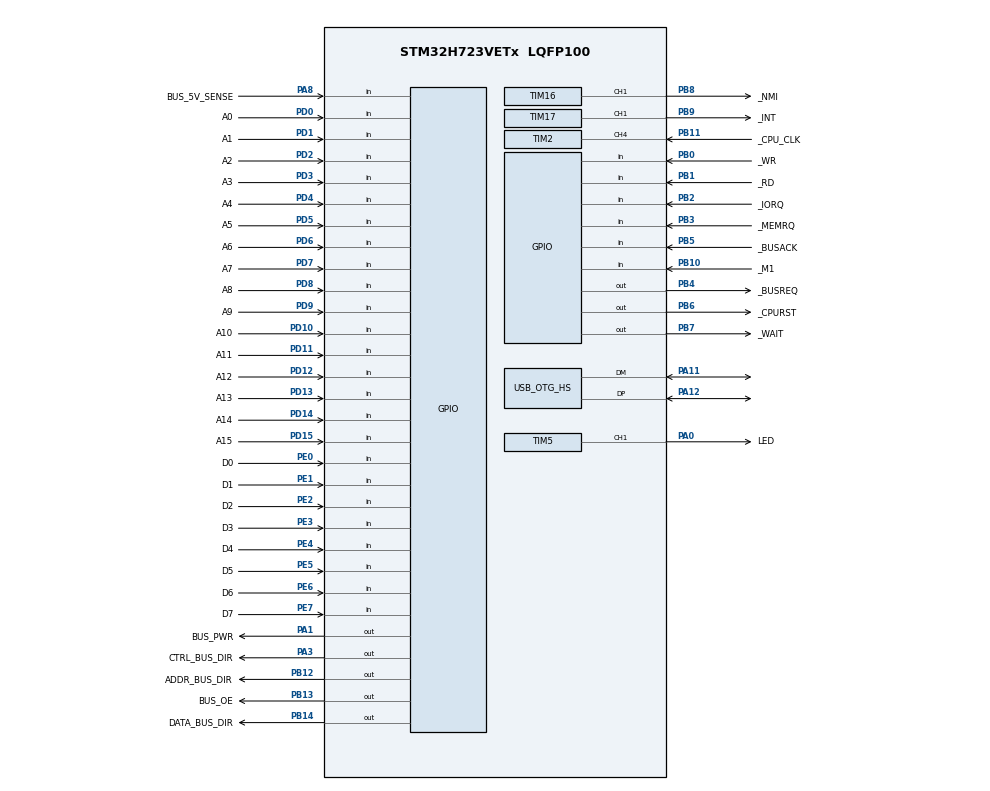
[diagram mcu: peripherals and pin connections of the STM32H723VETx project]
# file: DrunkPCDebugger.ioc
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CORTEX_M7.default_mode_Activation=1
Mcu.Family=STM32H7
Mcu.Name=STM32H723VETx
Mcu.Package=LQFP100
NVIC.OTG_HS_IRQn=true\:0\:0\:false\:false\:true\:false\:true\:true
NVIC.PriorityGroup=NVIC_PRIORITYGROUP_4
PA0.GPIO_Label=LED
PA0.GPIO_PuPd=GPIO_PULLUP
PA0.Signal=S_TIM5_CH1
PA1.GPIO_Label=BUS_PWR
PA1.Signal=GPIO_Output
PA11.Mode=Device_Only_FS
PA11.Signal=USB_OTG_HS_DM
PA12.Mode=Device_Only_FS
PA12.Signal=USB_OTG_HS_DP
PA13(JTMS/SWDIO).Mode=Serial_Wire
PA13(JTMS/SWDIO).Signal=DEBUG_JTMS-SWDIO
PA14(JTCK/SWCLK).Mode=Serial_Wire
PA14(JTCK/SWCLK).Signal=DEBUG_JTCK-SWCLK
PA3.GPIO_Label=CTRL_BUS_DIR
PA3.Signal=GPIO_Output
PA8.GPIO_Label=BUS_5V_SENSE
PA8.Signal=GPIO_Input
PB0.GPIO_Label=_WR
PB0.Signal=GPIO_Input
PB1.GPIO_Label=_RD
PB1.Signal=GPIO_Input
PB10.GPIO_Label=_M1
PB10.Signal=GPIO_Input
PB11.GPIO_Label=_CPU_CLK
PB11.Signal=S_TIM2_CH4
PB12.GPIO_Label=ADDR_BUS_DIR
PB12.Signal=GPIO_Output
PB13.GPIO_Label=BUS_OE
PB13.Signal=GPIO_Output
PB14.GPIO_Label=DATA_BUS_DIR
PB14.Signal=GPIO_Output
PB2.GPIO_Label=_IORQ
PB2.Signal=GPIO_Input
PB3(JTDO/TRACESWO).GPIO_Label=_MEMRQ
PB3(JTDO/TRACESWO).Signal=GPIO_Input
PB4(NJTRST).GPIO_Label=_BUSREQ
PB4(NJTRST).PinState=GPIO_PIN_SET
PB4(NJTRST).Signal=GPIO_Output
PB5.GPIO_Label=_BUSACK
PB5.Signal=GPIO_Input
PB6.GPIO_Label=_CPURST
PB6.PinState=GPIO_PIN_SET
PB6.Signal=GPIO_Output
PB7.GPIO_Label=_WAIT
PB7.GPIO_PuPd=GPIO_PULLUP
PB7.Signal=GPIO_Output
PB8.GPIO_Label=_NMI
PB8.GPIO_PuPd=GPIO_PULLUP
PB8.Signal=S_TIM16_CH1
PB9.GPIO_Label=_INT
PB9.GPIO_PuPd=GPIO_PULLUP
PB9.Signal=S_TIM17_CH1
PD0.GPIO_Label=A0
PD0.Signal=GPIO_Input
PD1.GPIO_Label=A1
PD1.Signal=GPIO_Input
PD10.GPIO_Label=A10
PD10.Signal=GPIO_Input
PD11.GPIO_Label=A11
PD11.Signal=GPIO_Input
PD12.GPIO_Label=A12
PD12.Signal=GPIO_Input
PD13.GPIO_Label=A13
PD13.Signal=GPIO_Input
PD14.GPIO_Label=A14
PD14.Signal=GPIO_Input
PD15.GPIO_Label=A15
PD15.Signal=GPIO_Input
PD2.GPIO_Label=A2
PD2.Signal=GPIO_Input
PD3.GPIO_Label=A3
PD3.Signal=GPIO_Input
PD4.GPIO_Label=A4
PD4.Signal=GPIO_Input
PD5.GPIO_Label=A5
PD5.Signal=GPIO_Input
PD6.GPIO_Label=A6
PD6.Signal=GPIO_Input
PD7.GPIO_Label=A7
PD7.Signal=GPIO_Input
PD8.GPIO_Label=A8
PD8.Signal=GPIO_Input
PD9.GPIO_Label=A9
PD9.Signal=GPIO_Input
PE0.GPIO_Label=D0
PE0.Signal=GPIO_Input
PE1.GPIO_Label=D1
PE1.Signal=GPIO_Input
PE2.GPIO_Label=D2
PE2.Signal=GPIO_Input
PE3.GPIO_Label=D3
PE3.Signal=GPIO_Input
PE4.GPIO_Label=D4
PE4.Signal=GPIO_Input
PE5.GPIO_Label=D5
PE5.Signal=GPIO_Input
PE6.GPIO_Label=D6
PE6.Signal=GPIO_Input
PE7.GPIO_Label=D7
PE7.Signal=GPIO_Input
PH0-OSC_IN.Mode=HSE-External-Oscillator
PH0-OSC_IN.Signal=RCC_OSC_IN
PH1-OSC_OUT.Mode=HSE-External-Oscillator
PH1-OSC_OUT.Signal=RCC_OSC_OUT
ProjectManager.HeapSize=0x200
ProjectManager.StackSize=0x400
ProjectManager.TargetToolchain=Makefile
RCC.ADCFreq_Value=50390625
RCC.APB1Freq_Value=137500000
RCC.APB2Freq_Value=137500000
RCC.APB3Freq_Value=137500000
RCC.APB4Freq_Value=137500000
RCC.CortexFreq_Value=550000000
RCC.D1PPRE=RCC_APB3_DIV2
RCC.D2PPRE1=RCC_APB1_DIV2
RCC.D2PPRE2=RCC_APB2_DIV2
RCC.D3PPRE=RCC_APB4_DIV2
RCC.DIVM1=2
RCC.DIVN1=44
RCC.DIVP1=1
RCC.DIVQ1=5
RCC.HCLKFreq_Value=275000000
RCC.HPRE=RCC_HCLK_DIV2
RCC.PLL2FRACN=0
RCC.PLL3FRACN=0
RCC.PLLFRACN=0
RCC.PLLSourceVirtual=RCC_PLLSOURCE_HSE
RCC.SYSCLKFreq_VALUE=550000000
RCC.SYSCLKSource=RCC_SYSCLKSOURCE_PLLCLK
RCC.USBCLockSelection=RCC_USBCLKSOURCE_HSI48
RCC.USBFreq_Value=48000000
SH.S_TIM16_CH1.0=TIM16_CH1,Output Compare1 CH1
SH.S_TIM17_CH1.0=TIM17_CH1,Output Compare1 CH1
SH.S_TIM2_CH4.0=TIM2_CH4,Input_Capture4_from_TI4
SH.S_TIM5_CH1.0=TIM5_CH1,PWM Generation1 CH1
TIM16.Channel=TIM_CHANNEL_1
TIM17.Channel=TIM_CHANNEL_1
TIM2.Channel-Input_Capture4_from_TI4=TIM_CHANNEL_4
TIM5.Channel-PWM\ Generation1\ CH1=TIM_CHANNEL_1
USB_DEVICE.CLASS_NAME_HS=CDC
USB_DEVICE.MANUFACTURER_STRING=DrunkBatya
USB_DEVICE.PRODUCT_STRING_CDC_HS=DrunkPC Debugger
USB_DEVICE.VirtualMode=Cdc
USB_DEVICE.VirtualModeHS=Cdc_HS
USB_OTG_HS.VirtualMode-Device_Only_FS=Device_Only_FS
VP_MEMORYMAP_VS_MEMORYMAP.Mode=CurAppReg
VP_RCC_USB.Mode=USB_HS
VP_TIM16_VS_ClockSourceINT.Mode=Enable_Timer
VP_TIM17_VS_ClockSourceINT.Mode=Enable_Timer
VP_USB_DEVICE_VS_USB_DEVICE_CDC_HS.Mode=CDC_HS
board=custom

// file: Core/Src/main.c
/* USER CODE BEGIN Header */
/**
  ******************************************************************************
  * @file           : main.c
  * @brief          : Main program body
  ******************************************************************************
  * @attention
  *
  * Copyright (c) 2026 STMicroelectronics.
  * All rights reserved.
  *
  * This software is licensed under terms that can be found in the LICENSE file
  * in the root directory of this software component.
  * If no LICENSE file comes with this software, it is provided AS-IS.
  *
  ******************************************************************************
  */
/* USER CODE END Header */
#include "main.h"
#include "tim.h"
#include "usb_device.h"
#include "gpio.h"

/* USER CODE BEGIN Includes */
#include <app_main.h>
#include <kal/kal.h>

/* USER CODE END Includes */

void SystemClock_Config(void);
static void MPU_Config(void);

int main(void)
{

  /* MPU Configuration--------------------------------------------------------*/
  MPU_Config();

  /* MCU Configuration--------------------------------------------------------*/

  /* Reset of all peripherals, Initializes the Flash interface and the Systick. */
  HAL_Init();

  /* Configure the system clock */
  SystemClock_Config();

  /* Initialize all configured peripherals */
  MX_GPIO_Init();
  MX_TIM2_Init();
  MX_TIM5_Init();
  MX_TIM16_Init();
  MX_TIM17_Init();
  MX_USB_DEVICE_Init();
  /* USER CODE BEGIN 2 */
  app_main();

  /* USER CODE END 2 */

  /* Infinite loop */
  while (1)
  {

  }
}

void SystemClock_Config(void)
{
  LL_FLASH_SetLatency(LL_FLASH_LATENCY_3);
  while(LL_FLASH_GetLatency()!= LL_FLASH_LATENCY_3)
  {
  }
  LL_PWR_ConfigSupply(LL_PWR_LDO_SUPPLY);
  LL_PWR_SetRegulVoltageScaling(LL_PWR_REGU_VOLTAGE_SCALE0);
  while (LL_PWR_IsActiveFlag_VOS() == 0)
  {
  }
  LL_RCC_HSE_Enable();

   /* Wait till HSE is ready */
  while(LL_RCC_HSE_IsReady() != 1)
  {

  }
  LL_RCC_HSI48_Enable();

   /* Wait till HSI48 is ready */
  while(LL_RCC_HSI48_IsReady() != 1)
  {

  }
  LL_RCC_PLL_SetSource(LL_RCC_PLLSOURCE_HSE);
  LL_RCC_PLL1P_Enable();
  LL_RCC_PLL1R_Enable();
  LL_RCC_PLL1_SetVCOInputRange(LL_RCC_PLLINPUTRANGE_8_16);
  LL_RCC_PLL1_SetVCOOutputRange(LL_RCC_PLLVCORANGE_WIDE);
  LL_RCC_PLL1_SetM(2);
  LL_RCC_PLL1_SetN(44);
  LL_RCC_PLL1_SetP(1);
  LL_RCC_PLL1_SetQ(5);
  LL_RCC_PLL1_SetR(2);
  LL_RCC_PLL1_Enable();

   /* Wait till PLL is ready */
  while(LL_RCC_PLL1_IsReady() != 1)
  {
  }

   /* Intermediate AHB prescaler 2 when target frequency clock is higher than 80 MHz */
   LL_RCC_SetAHBPrescaler(LL_RCC_AHB_DIV_2);

  LL_RCC_SetSysClkSource(LL_RCC_SYS_CLKSOURCE_PLL1);

   /* Wait till System clock is ready */
  while(LL_RCC_GetSysClkSource() != LL_RCC_SYS_CLKSOURCE_STATUS_PLL1)
  {

  }
  LL_RCC_SetSysPrescaler(LL_RCC_SYSCLK_DIV_1);
  LL_RCC_SetAHBPrescaler(LL_RCC_AHB_DIV_2);
  LL_RCC_SetAPB1Prescaler(LL_RCC_APB1_DIV_2);
  LL_RCC_SetAPB2Prescaler(LL_RCC_APB2_DIV_2);
  LL_RCC_SetAPB3Prescaler(LL_RCC_APB3_DIV_2);
  LL_RCC_SetAPB4Prescaler(LL_RCC_APB4_DIV_2);
  LL_SetSystemCoreClock(550000000);

   /* Update the time base */
  if (HAL_InitTick (TICK_INT_PRIORITY) != HAL_OK)
  {
    Error_Handler();
  }
  LL_CRS_SetSyncDivider(LL_CRS_SYNC_DIV_1);
  LL_CRS_SetSyncPolarity(LL_CRS_SYNC_POLARITY_RISING);
  LL_CRS_SetSyncSignalSource(LL_CRS_SYNC_SOURCE_USB);
  LL_CRS_SetReloadCounter(__LL_CRS_CALC_CALCULATE_RELOADVALUE(48000000,1000));
  LL_CRS_SetFreqErrorLimit(34);
  LL_CRS_SetHSI48SmoothTrimming(32);
}

 /* MPU Configuration */

void MPU_Config(void)
{

  /* Disables the MPU */
  LL_MPU_Disable();

  /** Initializes and configures the Region and the memory to be protected
  */
  LL_MPU_ConfigRegion(LL_MPU_REGION_NUMBER0, 0x87, 0x0, LL_MPU_REGION_SIZE_4GB|LL_MPU_TEX_LEVEL0|LL_MPU_REGION_NO_ACCESS|LL_MPU_INSTRUCTION_ACCESS_DISABLE|LL_MPU_ACCESS_SHAREABLE|LL_MPU_ACCESS_NOT_CACHEABLE|LL_MPU_ACCESS_NOT_BUFFERABLE);
  /* Enables the MPU */
  LL_MPU_Enable(LL_MPU_CTRL_PRIVILEGED_DEFAULT);

}

void Error_Handler(void)
{
  /* USER CODE BEGIN Error_Handler_Debug */
  kal_crash();
  /* User can add his own implementation to report the HAL error return state */
  __disable_irq();
  while (1)
  {
  }
  /* USER CODE END Error_Handler_Debug */
}
